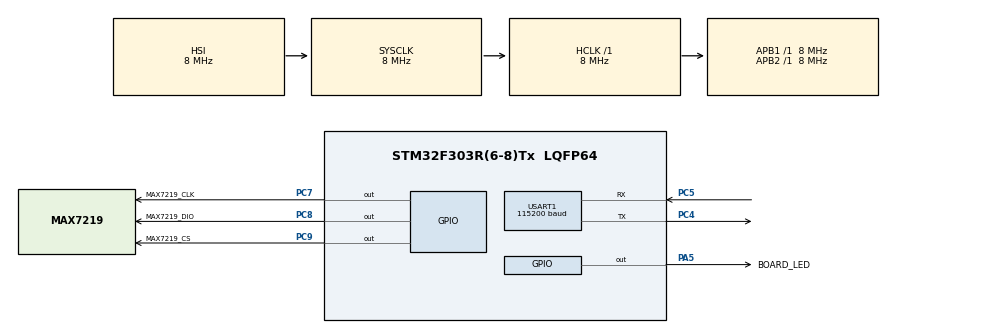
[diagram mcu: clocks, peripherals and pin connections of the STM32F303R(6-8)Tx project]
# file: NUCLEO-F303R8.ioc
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Mcu.Family=STM32F3
Mcu.Name=STM32F303R(6-8)Tx
Mcu.Package=LQFP64
NVIC.PriorityGroup=NVIC_PRIORITYGROUP_4
PA13.Mode=Serial_Wire
PA13.Signal=SYS_JTMS-SWDIO
PA14.Mode=Serial_Wire
PA14.Signal=SYS_JTCK-SWCLK
PA5.GPIO_Label=BOARD_LED
PA5.GPIO_Speed=GPIO_SPEED_FREQ_HIGH
PA5.Signal=GPIO_Output
PC4.Mode=Asynchronous
PC4.Signal=USART1_TX
PC5.Mode=Asynchronous
PC5.Signal=USART1_RX
PC7.GPIO_Label=MAX7219_CLK
PC7.GPIO_Speed=GPIO_SPEED_FREQ_HIGH
PC7.Signal=GPIO_Output
PC8.GPIO_Label=MAX7219_DIO
PC8.GPIO_Speed=GPIO_SPEED_FREQ_HIGH
PC8.Signal=GPIO_Output
PC9.GPIO_Label=MAX7219_CS
PC9.GPIO_Speed=GPIO_SPEED_FREQ_HIGH
PC9.PinState=GPIO_PIN_SET
PC9.Signal=GPIO_Output
PF0\ /\ OSC_IN.Mode=HSE-External-Oscillator
PF0\ /\ OSC_IN.Signal=RCC_OSC_IN
PF1\ /\ OSC_OUT.Mode=HSE-External-Oscillator
PF1\ /\ OSC_OUT.Signal=RCC_OSC_OUT
ProjectManager.HeapSize=0x200
ProjectManager.StackSize=0x400
ProjectManager.TargetToolchain=CMake
RCC.AHBFreq_Value=8000000
RCC.APB1Freq_Value=8000000
RCC.APB2Freq_Value=8000000
RCC.CortexFreq_Value=8000000
RCC.HSE_VALUE=8000000
RCC.HSI_VALUE=8000000
RCC.LSE_VALUE=32768
RCC.SYSCLKFreq_VALUE=8000000
USART1.BaudRate=115200
USART1.VirtualMode-Asynchronous=VM_ASYNC
board=custom

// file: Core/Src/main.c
/* USER CODE BEGIN Header */
/**
  ******************************************************************************
  * @file           : main.c
  * @brief          : Main program body
  ******************************************************************************
  * @attention
  *
  * Copyright (c) 2024 STMicroelectronics.
  * All rights reserved.
  *
  * This software is licensed under terms that can be found in the LICENSE file
  * in the root directory of this software component.
  * If no LICENSE file comes with this software, it is provided AS-IS.
  *
  ******************************************************************************
  */
/* USER CODE END Header */
#include "main.h"
#include "usart.h"
#include "gpio.h"

/* USER CODE BEGIN Includes */
#include "max7219.h"
/* USER CODE END Includes */

/* USER CODE BEGIN PV */

int count = 0;

/* USER CODE END PV */

void SystemClock_Config(void);

int main(void)
{

  /* MCU Configuration--------------------------------------------------------*/

  /* Reset of all peripherals, Initializes the Flash interface and the Systick. */
  HAL_Init();

  /* Configure the system clock */
  SystemClock_Config();

  /* Initialize all configured peripherals */
  MX_GPIO_Init();
  MX_USART1_UART_Init();
  /* USER CODE BEGIN 2 */
  MAX7219_Begin();
  /* USER CODE END 2 */

  /* Infinite loop */
  while (1)
  {

    /* USER CODE BEGIN 3 */
    HAL_GPIO_TogglePin(BOARD_LED_GPIO_Port, BOARD_LED_Pin);
    HAL_Delay(300);
    MAX7219_printf("%d", count);
    count++;
  }
  /* USER CODE END 3 */
}

void SystemClock_Config(void)
{
  RCC_OscInitTypeDef RCC_OscInitStruct = {0};
  RCC_ClkInitTypeDef RCC_ClkInitStruct = {0};
  RCC_PeriphCLKInitTypeDef PeriphClkInit = {0};

  /** Initializes the RCC Oscillators according to the specified parameters
  * in the RCC_OscInitTypeDef structure.
  */
  RCC_OscInitStruct.OscillatorType = RCC_OSCILLATORTYPE_HSI;
  RCC_OscInitStruct.HSIState = RCC_HSI_ON;
  RCC_OscInitStruct.HSICalibrationValue = RCC_HSICALIBRATION_DEFAULT;
  RCC_OscInitStruct.PLL.PLLState = RCC_PLL_NONE;
  if (HAL_RCC_OscConfig(&RCC_OscInitStruct) != HAL_OK)
  {
    Error_Handler();
  }

  /** Initializes the CPU, AHB and APB buses clocks
  */
  RCC_ClkInitStruct.ClockType = RCC_CLOCKTYPE_HCLK|RCC_CLOCKTYPE_SYSCLK
                              |RCC_CLOCKTYPE_PCLK1|RCC_CLOCKTYPE_PCLK2;
  RCC_ClkInitStruct.SYSCLKSource = RCC_SYSCLKSOURCE_HSI;
  RCC_ClkInitStruct.AHBCLKDivider = RCC_SYSCLK_DIV1;
  RCC_ClkInitStruct.APB1CLKDivider = RCC_HCLK_DIV1;
  RCC_ClkInitStruct.APB2CLKDivider = RCC_HCLK_DIV1;

  if (HAL_RCC_ClockConfig(&RCC_ClkInitStruct, FLASH_LATENCY_0) != HAL_OK)
  {
    Error_Handler();
  }
  PeriphClkInit.PeriphClockSelection = RCC_PERIPHCLK_USART1;
  PeriphClkInit.Usart1ClockSelection = RCC_USART1CLKSOURCE_PCLK1;
  if (HAL_RCCEx_PeriphCLKConfig(&PeriphClkInit) != HAL_OK)
  {
    Error_Handler();
  }
}

void Error_Handler(void)
{
  __disable_irq();
  while (1)
  {
  }
}
